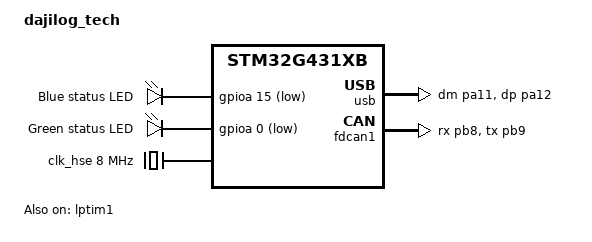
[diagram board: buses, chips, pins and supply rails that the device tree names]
/*
 * Copyright (c) 2026
 * SPDX-License-Identifier: Apache-2.0
 */

/dts-v1/;
#include <st/g4/stm32g431Xb.dtsi>
#include <st/g4/stm32g431c(6-8-b)tx-pinctrl.dtsi>

/ {
	model = "dajilog_tech";
	compatible = "dajilog_tech,dajilog-tech";

	chosen {
		zephyr,sram = &sram0;
		zephyr,flash = &flash0;
		zephyr,canbus = &fdcan1;
	};

	aliases {
		led0 = &blue_led;
		led1 = &green_led;
	};

	leds {
		compatible = "gpio-leds";

		blue_led: led_0 {
			gpios = <&gpioa 15 GPIO_ACTIVE_LOW>;
			label = "Blue status LED";
		};

		green_led: led_1 {
			gpios = <&gpioa 0 GPIO_ACTIVE_LOW>;
			label = "Green status LED";
		};
	};
};

&clk_hsi {
	status = "disabled";
};

&clk_hse {
	status = "okay";
	clock-frequency = <DT_FREQ_M(8)>;
};

&pll {
	div-m = <2>;
	mul-n = <72>;
	div-p = <2>;
	div-q = <6>;
	div-r = <2>;
	clocks = <&clk_hse>;
	status = "okay";
};

&rcc {
	clocks = <&pll>;
	clock-frequency = <DT_FREQ_M(144)>;
	ahb-prescaler = <1>;
	apb1-prescaler = <1>;
	apb2-prescaler = <1>;
};

stm32_lp_tick_source: &lptim1 {
	clocks = <&rcc STM32_CLOCK_BUS_APB1 0x80000000>,
		 <&rcc STM32_SRC_LSE LPTIM1_SEL(3)>;
	status = "okay";
};

zephyr_udc0: &usb {
	pinctrl-0 = <&usb_dm_pa11 &usb_dp_pa12>;
	pinctrl-names = "default";
	clocks = <&rcc STM32_CLOCK_BUS_APB1 0x00800000>,
		 <&rcc STM32_SRC_PLL_Q CLK48_SEL(2)>;
	status = "okay";
};

&fdcan1 {
	pinctrl-0 = <&fdcan1_rx_pb8 &fdcan1_tx_pb9>;
	pinctrl-names = "default";
	clocks = <&rcc STM32_CLOCK_BUS_APB1 0x02000000>,
		 <&rcc STM32_SRC_PLL_Q FDCAN_SEL(1)>;
	status = "okay";
};
